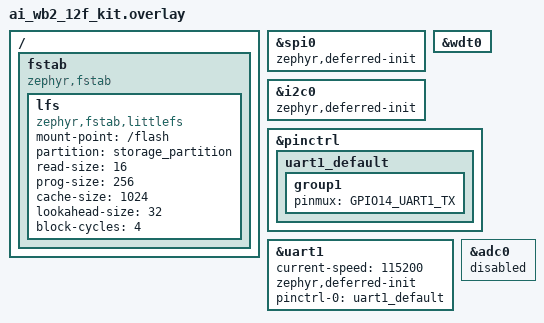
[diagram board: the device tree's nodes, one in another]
/*
 * Copyright (c) 2025 MASSDRIVER EI (massdriver.space)
 *
 * SPDX-License-Identifier: Apache-2.0
 */

/ {
	fstab {
		compatible = "zephyr,fstab";
		lfs: lfs {
			compatible = "zephyr,fstab,littlefs";
			mount-point = "/flash";
			partition = <&storage_partition>;
			read-size=<16>;
			prog-size=<256>;
			cache-size=<1024>;
			lookahead-size=<32>;
			block-cycles=<4>;
		};
	};
};

&spi0 {
	zephyr,deferred-init;
};

&i2c0 {
	zephyr,deferred-init;
};

&wdt0 {
	status = "okay";
};

&pinctrl {
	uart1_default: uart1_default {
		group1 {
			pinmux = <GPIO14_UART1_TX>;
		};
	};
};

&uart1 {
	status = "okay";
	current-speed = <115200>;
	zephyr,deferred-init;
	/* A pinctrl struct MUST have been allocated at build time to use dynamic pinctrl,
	 * but it can be nonsense if needed as the device is deferred-init
	 * and pinctrl won't be applied until device init.
	 */
	pinctrl-0 = <&uart1_default>;
	pinctrl-names = "default";

};

&adc0 {
	status = "disabled";
};
